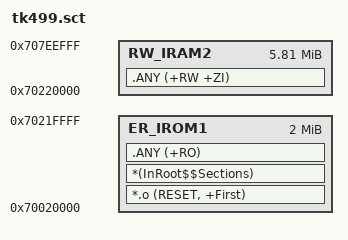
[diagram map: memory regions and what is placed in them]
; *************************************************************
; *** Scatter-Loading Description File generated by uVision ***
; *************************************************************

LR_IROM1 0x70020000 0x00200000  {    ; load region size_region
  ER_IROM1 0x70020000 0x00200000  {  ; load address = execution address
   *.o (RESET, +First)
   *(InRoot$$Sections)
   .ANY (+RO)
  }
  ;RW_IRAM1 0x70000000 0x00008000  {  ; RW data
   ;.ANY (+RW +ZI)
  ;}
  RW_IRAM2 0x70220000 0x005CF000  {
   .ANY (+RW +ZI)
  }
;  RW_IRAM3 0X20000400 0X200007ff { ; RW data
;  *.o(RAMCODE)
;  ;.ANY (+RW +ZI)
;  } 
}
